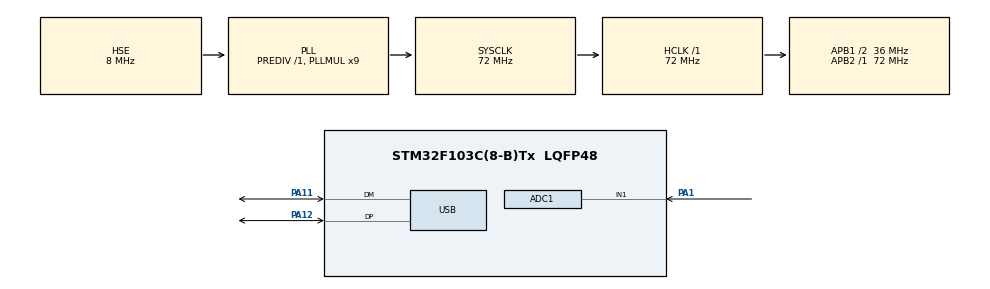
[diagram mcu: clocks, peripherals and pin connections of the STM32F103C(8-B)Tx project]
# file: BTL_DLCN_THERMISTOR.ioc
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ADC1.Channel-0\#ChannelRegularConversion=ADC_CHANNEL_1
ADC1.NbrOfConversionFlag=1
ADC1.Rank-0\#ChannelRegularConversion=1
ADC1.SamplingTime-0\#ChannelRegularConversion=ADC_SAMPLETIME_1CYCLE_5
ADC1.master=1
Mcu.Family=STM32F1
Mcu.Name=STM32F103C(8-B)Tx
Mcu.Package=LQFP48
NVIC.PriorityGroup=NVIC_PRIORITYGROUP_4
NVIC.USB_LP_CAN1_RX0_IRQn=true\:0\:0\:false\:false\:true\:false\:true\:true
PA1.Signal=ADCx_IN1
PA11.Mode=Device
PA11.Signal=USB_DM
PA12.Mode=Device
PA12.Signal=USB_DP
PA13.Mode=Serial_Wire
PA13.Signal=SYS_JTMS-SWDIO
PA14.Mode=Serial_Wire
PA14.Signal=SYS_JTCK-SWCLK
PD0-OSC_IN.Mode=HSE-External-Oscillator
PD0-OSC_IN.Signal=RCC_OSC_IN
PD1-OSC_OUT.Mode=HSE-External-Oscillator
PD1-OSC_OUT.Signal=RCC_OSC_OUT
ProjectManager.HeapSize=0x200
ProjectManager.StackSize=0x400
ProjectManager.TargetToolchain=MDK-ARM V5.32
RCC.ADCPresc=RCC_ADCPCLK2_DIV6
RCC.AHBFreq_Value=72000000
RCC.APB1CLKDivider=RCC_HCLK_DIV2
RCC.APB1Freq_Value=36000000
RCC.APB1TimFreq_Value=72000000
RCC.APB2Freq_Value=72000000
RCC.APB2TimFreq_Value=72000000
RCC.HCLKFreq_Value=72000000
RCC.PLLMUL=RCC_PLL_MUL9
RCC.PLLSourceVirtual=RCC_PLLSOURCE_HSE
RCC.SYSCLKFreq_VALUE=72000000
RCC.SYSCLKSource=RCC_SYSCLKSOURCE_PLLCLK
RCC.USBFreq_Value=48000000
RCC.USBPrescaler=RCC_USBCLKSOURCE_PLL_DIV1_5
SH.ADCx_IN1.0=ADC1_IN1,IN1
USB_DEVICE.CLASS_NAME_FS=CDC
USB_DEVICE.PRODUCT_STRING_CDC_FS=USB_VIRTUAL_COM_PORT
USB_DEVICE.VirtualMode=Cdc
USB_DEVICE.VirtualModeFS=Cdc_FS
VP_USB_DEVICE_VS_USB_DEVICE_CDC_FS.Mode=CDC_FS
board=custom

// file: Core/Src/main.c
/* USER CODE BEGIN Header */
/**
  ******************************************************************************
  * @file           : main.c
  * @brief          : Main program body
  ******************************************************************************
  * @attention
  *
  * Copyright (c) 2025 STMicroelectronics.
  * All rights reserved.
  *
  * This software is licensed under terms that can be found in the LICENSE file
  * in the root directory of this software component.
  * If no LICENSE file comes with this software, it is provided AS-IS.
  *
  ******************************************************************************
  */
/* USER CODE END Header */
#include "main.h"
#include "usb_device.h"

/* USER CODE BEGIN Includes */
#include "usbd_cdc_if.h"
#include "string.h"
#include "math.h"
/* USER CODE END Includes */

/* USER CODE BEGIN PD */
uint32_t value = 0;
#define VOLTAGE_REF  3.3
#define ADC_SAMPLE_COUNT 20
#define Beta 3926.15
uint32_t adc_value[ADC_SAMPLE_COUNT];
uint32_t filtered_value =0;
char buffer[64];
float voltage_value = 0;
float ohm_value = 0;
float tempurate_value = 0;

/* USER CODE END PD */

ADC_HandleTypeDef hadc1;

void SystemClock_Config(void);
static void MX_GPIO_Init(void);
static void MX_ADC1_Init(void);

int main(void)
{

  /* MCU Configuration--------------------------------------------------------*/

  /* Reset of all peripherals, Initializes the Flash interface and the Systick. */
  HAL_Init();

  /* Configure the system clock */
  SystemClock_Config();

  /* Initialize all configured peripherals */
  MX_GPIO_Init();
  MX_ADC1_Init();
  MX_USB_DEVICE_Init();

  /* Infinite loop */
  /* USER CODE BEGIN WHILE */
  while (1)
  {
		uint32_t sum = 0;

		for(int i = 0; i < ADC_SAMPLE_COUNT; i++){
			HAL_ADC_Start(&hadc1);
			HAL_ADC_PollForConversion(&hadc1, 10);
			adc_value[i] = HAL_ADC_GetValue(&hadc1);
			HAL_ADC_Stop(&hadc1);
			HAL_Delay(10);
		}
		for(int i = 0; i < ADC_SAMPLE_COUNT; i++){
			sum += adc_value[i];
		}
		filtered_value = sum / ADC_SAMPLE_COUNT;
		voltage_value = ((float)filtered_value/4095.0f)*VOLTAGE_REF;
		ohm_value = ((VOLTAGE_REF*10*1000)/voltage_value) - (10*1000);
		float pre_tempurate_value = ((1/(25+273.13) + (log(ohm_value/10000)/Beta)));
		tempurate_value = (1/pre_tempurate_value) - 273.13;
		sprintf(buffer,"%.2f\r\n", tempurate_value);
		CDC_Transmit_FS((uint8_t*)buffer, strlen(buffer));
    /* USER CODE END WHILE */

  }
}

void SystemClock_Config(void)
{
  RCC_OscInitTypeDef RCC_OscInitStruct = {0};
  RCC_ClkInitTypeDef RCC_ClkInitStruct = {0};
  RCC_PeriphCLKInitTypeDef PeriphClkInit = {0};

  /** Initializes the RCC Oscillators according to the specified parameters
  * in the RCC_OscInitTypeDef structure.
  */
  RCC_OscInitStruct.OscillatorType = RCC_OSCILLATORTYPE_HSE;
  RCC_OscInitStruct.HSEState = RCC_HSE_ON;
  RCC_OscInitStruct.HSEPredivValue = RCC_HSE_PREDIV_DIV1;
  RCC_OscInitStruct.HSIState = RCC_HSI_ON;
  RCC_OscInitStruct.PLL.PLLState = RCC_PLL_ON;
  RCC_OscInitStruct.PLL.PLLSource = RCC_PLLSOURCE_HSE;
  RCC_OscInitStruct.PLL.PLLMUL = RCC_PLL_MUL9;
  if (HAL_RCC_OscConfig(&RCC_OscInitStruct) != HAL_OK)
  {
    Error_Handler();
  }

  /** Initializes the CPU, AHB and APB buses clocks
  */
  RCC_ClkInitStruct.ClockType = RCC_CLOCKTYPE_HCLK|RCC_CLOCKTYPE_SYSCLK
                              |RCC_CLOCKTYPE_PCLK1|RCC_CLOCKTYPE_PCLK2;
  RCC_ClkInitStruct.SYSCLKSource = RCC_SYSCLKSOURCE_PLLCLK;
  RCC_ClkInitStruct.AHBCLKDivider = RCC_SYSCLK_DIV1;
  RCC_ClkInitStruct.APB1CLKDivider = RCC_HCLK_DIV2;
  RCC_ClkInitStruct.APB2CLKDivider = RCC_HCLK_DIV1;

  if (HAL_RCC_ClockConfig(&RCC_ClkInitStruct, FLASH_LATENCY_2) != HAL_OK)
  {
    Error_Handler();
  }
  PeriphClkInit.PeriphClockSelection = RCC_PERIPHCLK_ADC|RCC_PERIPHCLK_USB;
  PeriphClkInit.AdcClockSelection = RCC_ADCPCLK2_DIV6;
  PeriphClkInit.UsbClockSelection = RCC_USBCLKSOURCE_PLL_DIV1_5;
  if (HAL_RCCEx_PeriphCLKConfig(&PeriphClkInit) != HAL_OK)
  {
    Error_Handler();
  }
}

static void MX_ADC1_Init(void)
{

  ADC_ChannelConfTypeDef sConfig = {0};

  /** Common config
  */
  hadc1.Instance = ADC1;
  hadc1.Init.ScanConvMode = ADC_SCAN_DISABLE;
  hadc1.Init.ContinuousConvMode = DISABLE;
  hadc1.Init.DiscontinuousConvMode = DISABLE;
  hadc1.Init.ExternalTrigConv = ADC_SOFTWARE_START;
  hadc1.Init.DataAlign = ADC_DATAALIGN_RIGHT;
  hadc1.Init.NbrOfConversion = 1;
  if (HAL_ADC_Init(&hadc1) != HAL_OK)
  {
    Error_Handler();
  }

  /** Configure Regular Channel
  */
  sConfig.Channel = ADC_CHANNEL_1;
  sConfig.Rank = ADC_REGULAR_RANK_1;
  sConfig.SamplingTime = ADC_SAMPLETIME_1CYCLE_5;
  if (HAL_ADC_ConfigChannel(&hadc1, &sConfig) != HAL_OK)
  {
    Error_Handler();
  }

}

static void MX_GPIO_Init(void)
{

  /* GPIO Ports Clock Enable */
  __HAL_RCC_GPIOD_CLK_ENABLE();
  __HAL_RCC_GPIOA_CLK_ENABLE();

}

void Error_Handler(void)
{
  __disable_irq();
  while (1)
  {
  }
}
